# elastic_buffer_apb_regs: IP-XACT component
VLNV mohamed_tarek:flat:elastic_buffer_apb_regs:1.0
IP-XACT template for APB wrapper register model of elastic buffer

## Address spaces and blocks
apb_map.eb_regs: base 'hA0000000, range 'h28, width 32, register

## Registers
Registers are 32-bit, read-write, reset 0x0 unless marked. A register's access mark holds for its fields unless they carry their own. Offsets are from the block's base; lines under a group give offsets from that group; [hi:lo] are bit positions; {n}, {i} and the like mark numbered series; 'fields as' and 'values as' point back to an identical list; <NAME> marks a mode.

## apb_map.eb_regs
Base 0xA0000000
0x00 EB_CTRL — Elastic buffer control register
  [0] enable
0x04 EB_COR_CFG_MAX — Threshold for SKP drops
  [5:0] cor_max
0x08 EB_COR_CFG_MIN — Threshold for SKP insertions
  [5:0] cor_min
0x0C EB_COR_SEQ1 — SKP sequence value 1
  [19:0] cor_seq1
0x10 EB_COR_SEQ2 — SKP sequence value 2
  [19:0] cor_seq2
0x14 EB_FILL_LEVEL ro — Current elastic buffer fill level
  [5:0] fill_level
0x18 EB_SKP_ADD_CNT ro — SKP add event count
  [15:0] skp_add_cnt
0x1C EB_SKP_RM_CNT ro — SKP remove event count
  [15:0] skp_rm_cnt
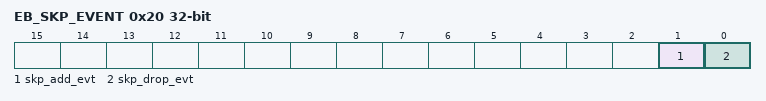
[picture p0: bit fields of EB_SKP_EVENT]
0x20 EB_SKP_EVENT ro — Pulse status for SKP events
  [1] skp_add_evt, [0] skp_drop_evt
0x24 EB_ERR_STATUS ro — Error status flags from elastic buffer
  [2:0] err_status
